# AT32UC3L032 device description
Architecture: AVR32_UC3; Family: AVR UC3
Registers are 32-bit, read-write, reset 0x0 unless marked. A register's access mark holds for its fields unless they carry their own. Offsets are from the block's base; [hi:lo] are bit positions; lines under a group give offsets from that group; {n}, {i} and the like mark numbered series; 'fields as' and 'values as' point back to an identical list.

## EIC — External Interrupt Controller
Instances: EIC 0xffff2400
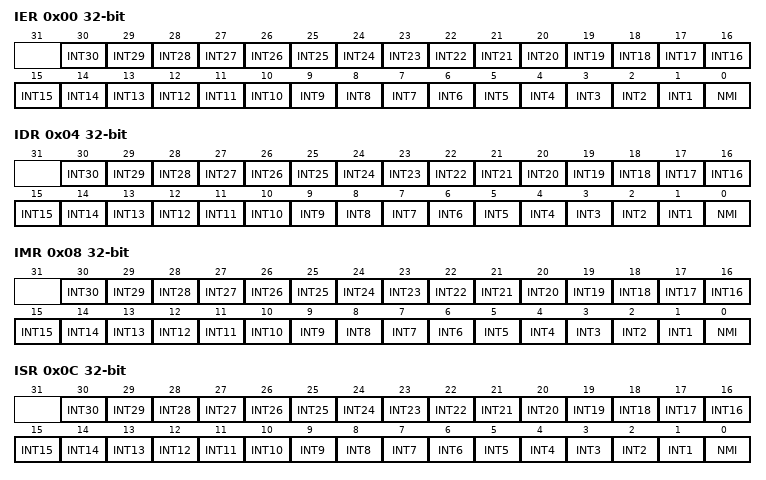
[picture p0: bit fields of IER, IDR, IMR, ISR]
0x00 IER wo — Interrupt Enable Register
  [n] INT{n} (n=1..30) — External Interrupt {n}
  [0] NMI — External Non Maskable CPU interrupt
0x04 IDR wo — Interrupt Disable Register
  fields as IER
0x08 IMR ro — Interrupt Mask Register
  fields as IER
0x0C ISR ro — Interrupt Status Register
  fields as IER
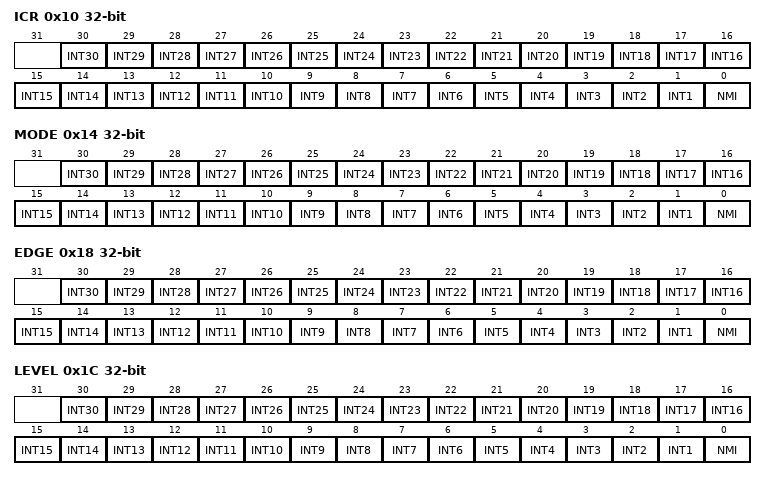
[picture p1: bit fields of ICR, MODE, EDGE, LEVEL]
0x10 ICR wo — Interrupt Clear Register
  fields as IER
0x14 MODE
  fields as IER
0x18 EDGE
  fields as IER
0x1C LEVEL
  fields as IER
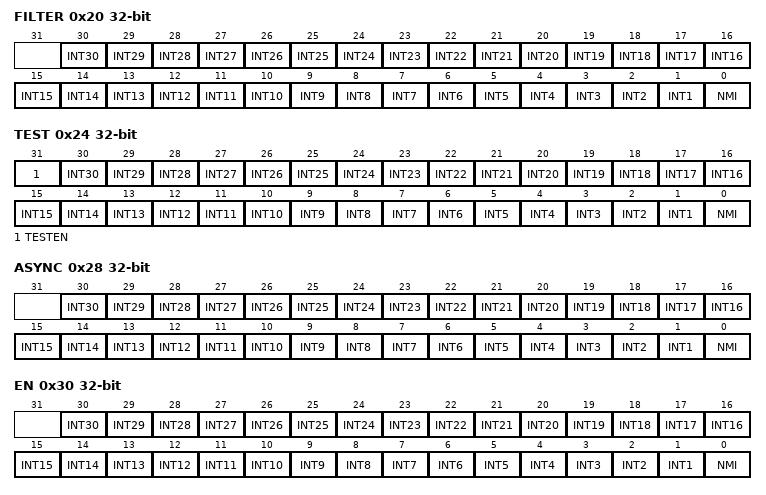
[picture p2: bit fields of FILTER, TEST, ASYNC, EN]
0x20 FILTER
  fields as IER
0x24 TEST
  [31] TESTEN — Test Enable
  [n] INT{n} (n=1..30) — External Interrupt {n}
  [0] NMI — External Non Maskable CPU interrupt
0x28 ASYNC — Asynchronous Mode Register
  fields as IER
0x30 EN wo — Enable Register
  fields as IER
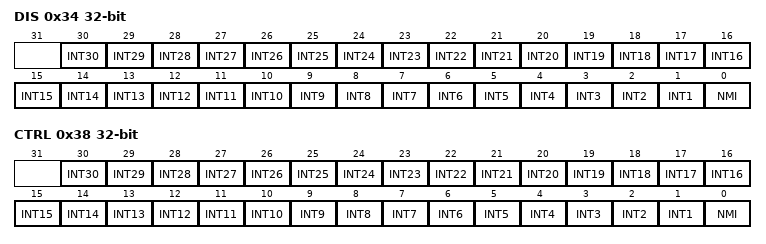
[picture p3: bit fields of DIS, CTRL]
0x34 DIS wo — Disable Register
  fields as IER
0x38 CTRL ro — Control Register
  fields as IER
0xFF VERSION ro reset 0x300
  [11:0] VERSION — Version bits

## FLASHCDW — Flash Controller
Instances: FLASHCDW 0xfffe0000
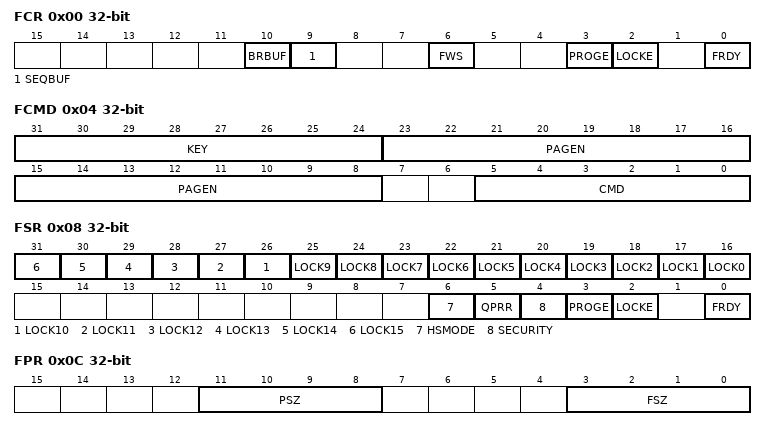
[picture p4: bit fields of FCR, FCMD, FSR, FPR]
0x00 FCR — Flash Controller Control Register
  [10] BRBUF, [9] SEQBUF, [6] FWS, [3] PROGE, [2] LOCKE, [0] FRDY
0x04 FCMD — Flash Controller Command Register
  [31:24] KEY
    165=KEY
  [23:8] PAGEN
  [5:0] CMD — Command
    0=NOP; 1=WP; 2=EP; 3=CPB; 4=LP; 5=UP; 6=EA; 7=WGPB; 8=EGPB; 9=SSB; 10=PGPFB; 11=EAGPF; 12=QPR; 13=WUP; 14=EUP; 15=QPRUP; 16=HSEN; 17=HSDIS
0x08 FSR reset not defined — Flash Controller Status Register
  [n+16] LOCK{n} (n=0..15), [6] HSMODE, [5] QPRR, [4] SECURITY, [3] PROGE, [2] LOCKE, [0] FRDY
0x0C FPR access not given reset not defined — Flash Controller Parameter Register
  [11:8] PSZ, [3:0] FSZ
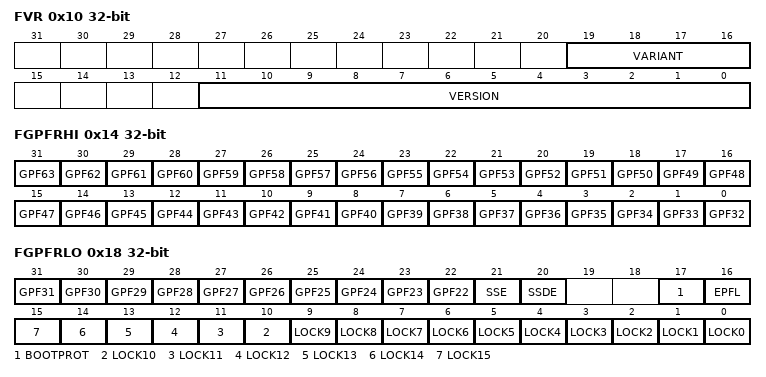
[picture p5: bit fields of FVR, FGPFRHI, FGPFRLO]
0x10 FVR access not given reset not defined — Flash Controller Version Register
  [19:16] VARIANT, [11:0] VERSION
0x14 FGPFRHI ro reset not defined — Flash Controller General Purpose Fuse Register High
  [n-32] GPF{n} (n=32..63)
0x18 FGPFRLO ro reset not defined — Flash Controller General Purpose Fuse Register Low
  [n] GPF{n} (n=22..31), [21] SSE, [20] SSDE, [17] BOOTPROT, [16] EPFL, [n] LOCK{n} (n=0..15)

## FREQM — Frequency Meter
Instances: FREQM 0xffff2800
0x00 CTRL wo — Frequency Meter Control register
  [0] START — Start frequency measurement
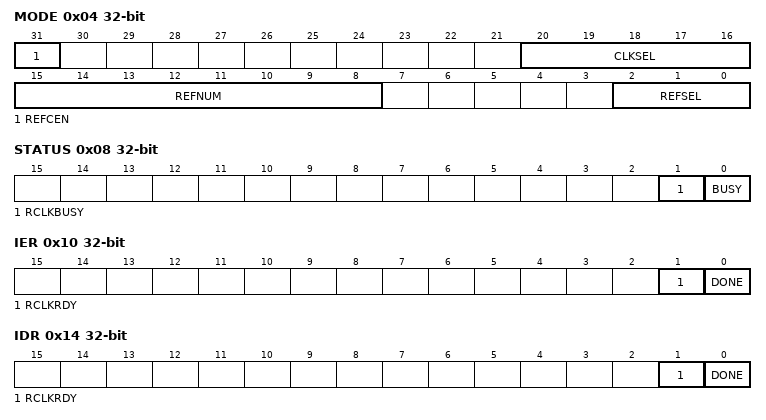
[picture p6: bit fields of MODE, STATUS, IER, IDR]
0x04 MODE — Frequency Meter Mode register
  [31] REFCEN — Reference Clock Enable
  [20:16] CLKSEL — Clock Source Selection
  [15:8] REFNUM — Number of Reference CLock Cycles
  [2:0] REFSEL — Reference Clock Selection
0x08 STATUS ro — Frequency Meter Status register
  [1] RCLKBUSY
  [0] BUSY — Frequency measurement on-going
0x0C VALUE ro — Frequency Meter Value register
  [23:0] VALUE — Measured frequency
0x10 IER wo — Frequency Meter Interrupt Enable Register
  [1] RCLKRDY — Refernce Clock ready
  [0] DONE — Frequency measurment done
0x14 IDR wo — Frequency Meter Interrupt Diable Register
  fields as IER
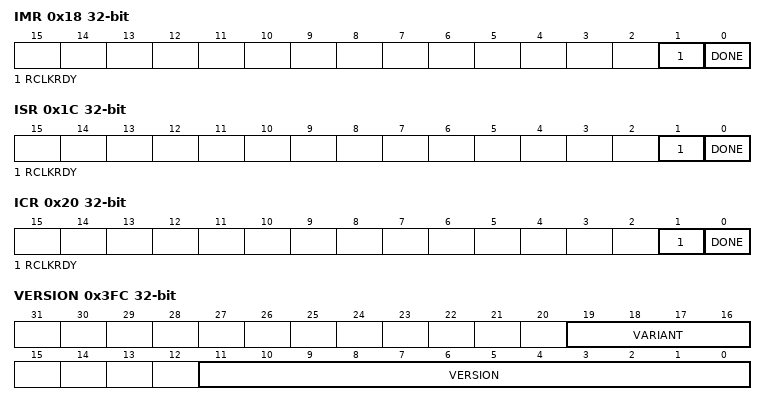
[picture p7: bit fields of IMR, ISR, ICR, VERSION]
0x18 IMR ro — Frequency Meter Interrupt Mask Register
  fields as IER
0x1C ISR ro — Frequency Meter Interrupt Status Register
  [1] RCLKRDY — Refernce Clock ready, set on 1 to 0 transaction on REF_CLK_BUSY in STATUS reg.
  [0] DONE — Frequency measurment done
0x20 ICR wo — Frequency Meter Interrupt Clear Register
  fields as IER
0x3FC VERSION ro reset not defined — Frequency Meter Version Register
  [19:16] VARIANT — Variant number
  [11:0] VERSION — Version number

## GLOC — Glue Logic Controller
Instances: GLOC 0xffff6c00
{0x0+8i} LUT[{i}] (i=0..6) group
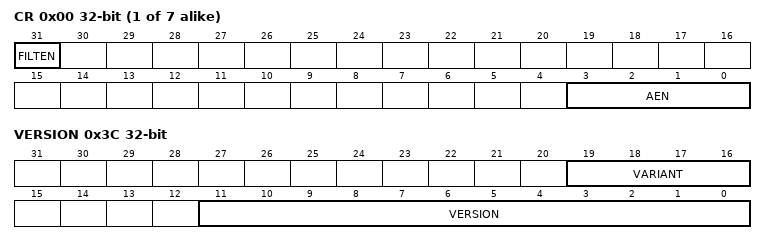
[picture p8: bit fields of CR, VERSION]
  0x00 CR — Control Register
    [31] FILTEN — Filter enable
    [3:0] AEN — Input mask
  0x04 TRUTH
    [15:0] TRUTH
0x38 PARAMETER ro reset not defined
  [7:0] LUTS
0x3C VERSION ro reset not defined
  [19:16] VARIANT, [11:0] VERSION

## HMATRIXB — HSB Matrix
Instances: HMATRIXB 0xfffe0400
{0x0+4i} mcfg[{i}] (i=0..15) access not given reset 0x2
  [2:0] ULBT — Undefined Length Burst Type
    0=INFINITE; 1=SINGLE; 2=FOUR_BEAT; 3=EIGHT_BEAT; 4=SIXTEEN_BEAT
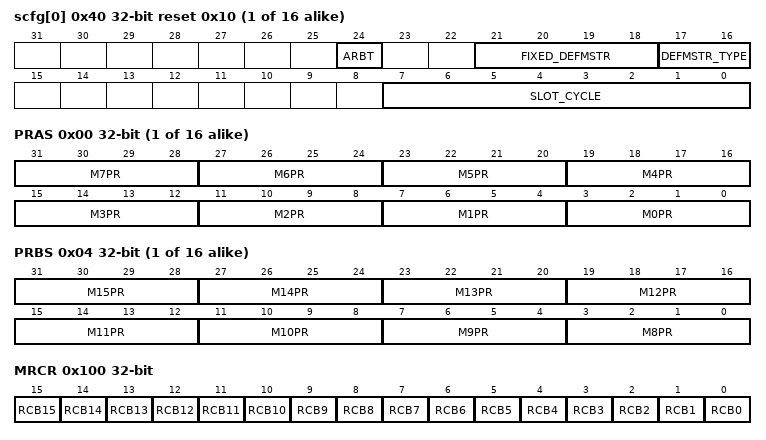
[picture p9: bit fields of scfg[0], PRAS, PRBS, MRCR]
{0x40+4i} scfg[{i}] (i=0..15) access not given reset 0x10
  [24] ARBT — Arbitration Type
    0=ROUND_ROBIN; 1=FIXED_PRIORITY
  [21:18] FIXED_DEFMSTR — Fixed Index of Default Master
  [17:16] DEFMSTR_TYPE — Default Master Type
    0=NO_DEFAULT; 1=LAST_DEFAULT; 2=FIXED_DEFAULT
  [7:0] SLOT_CYCLE — Maximum Number of Allowed Cycles for a Burst
{0x80+8i} prs[{i}] (i=0..15) group
  0x00 PRAS — Priority Register A for Slave 0
    [4n+3:4n] M{n}PR (n=0..7) — Master {n} Priority
  0x04 PRBS — Priority Register B for Slave 0
    [4n-29:4n-32] M{n}PR (n=8..15) — Master {n} Priority
0x100 MRCR — Master Remap Control Register
  [n] RCB{n} (n=0..15) — Remap Command bit for Master {n}
{0x110+4i} sfr[{i}] (i=0..15) access not given
  [31:0] SFR — Special Function Register
